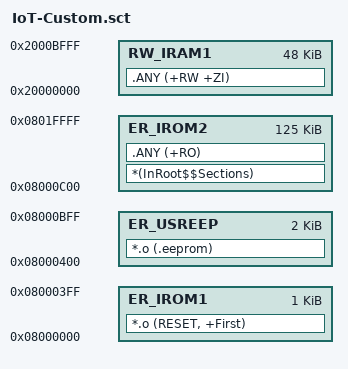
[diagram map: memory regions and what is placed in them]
; *************************************************************
; *** Scatter-Loading Description File generated by uVision ***
; *************************************************************

LR_IROM1 0x08000000 0x000400  {    ; load region size_region
  ER_IROM1 0x08000000 0x000400  {  ; load address = execution address
   *.o (RESET, +First)
  }
  RW_IRAM1 0x20000000 0x0000C000  {  ; RW data
   .ANY (+RW +ZI)
  }
}
LR_IROM2 0x08000C00 0x0001f400 {
  ER_IROM2 0x08000C00 0x0001f400  {  ; load address = execution address
   *(InRoot$$Sections)
   .ANY (+RO)
  }
}
LR_IROM3 0x08000400 0x00000800{
  ER_USREEP 0x08000400 0x00000800  {  ; load address = execution address
   *.o (.eeprom)
  }
}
